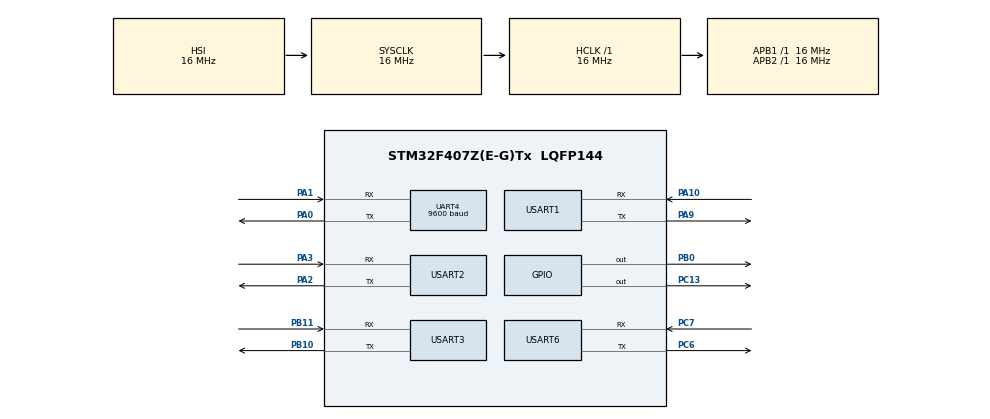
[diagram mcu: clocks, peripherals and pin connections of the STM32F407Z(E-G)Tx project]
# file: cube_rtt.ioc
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Dma.Request0=USART3_RX
Dma.Request1=UART4_RX
Dma.UART4_RX.1.Direction=DMA_PERIPH_TO_MEMORY
Dma.UART4_RX.1.FIFOMode=DMA_FIFOMODE_DISABLE
Dma.UART4_RX.1.Instance=DMA1_Stream2
Dma.UART4_RX.1.MemDataAlignment=DMA_MDATAALIGN_BYTE
Dma.UART4_RX.1.MemInc=DMA_MINC_ENABLE
Dma.UART4_RX.1.Mode=DMA_NORMAL
Dma.UART4_RX.1.PeriphDataAlignment=DMA_PDATAALIGN_BYTE
Dma.UART4_RX.1.PeriphInc=DMA_PINC_DISABLE
Dma.UART4_RX.1.Priority=DMA_PRIORITY_LOW
Dma.USART3_RX.0.Direction=DMA_PERIPH_TO_MEMORY
Dma.USART3_RX.0.FIFOMode=DMA_FIFOMODE_DISABLE
Dma.USART3_RX.0.Instance=DMA1_Stream1
Dma.USART3_RX.0.MemDataAlignment=DMA_MDATAALIGN_BYTE
Dma.USART3_RX.0.MemInc=DMA_MINC_ENABLE
Dma.USART3_RX.0.Mode=DMA_CIRCULAR
Dma.USART3_RX.0.PeriphDataAlignment=DMA_PDATAALIGN_BYTE
Dma.USART3_RX.0.PeriphInc=DMA_PINC_DISABLE
Dma.USART3_RX.0.Priority=DMA_PRIORITY_LOW
Mcu.Family=STM32F4
Mcu.Name=STM32F407Z(E-G)Tx
Mcu.Package=LQFP144
NVIC.DMA1_Stream1_IRQn=true\:0\:0\:false\:false\:true\:true\:false\:true\:true
NVIC.DMA1_Stream2_IRQn=true\:0\:0\:false\:false\:true\:true\:false\:true\:true
NVIC.PriorityGroup=NVIC_PRIORITYGROUP_4
NVIC.TIM6_DAC_IRQn=true\:15\:0\:false\:false\:true\:false\:false\:true\:true
NVIC.TimeBase=TIM6_DAC_IRQn
NVIC.TimeBaseIP=TIM6
NVIC.UART4_IRQn=true\:0\:0\:false\:false\:true\:false\:true\:true\:true
NVIC.USART3_IRQn=true\:0\:0\:false\:false\:true\:false\:true\:true\:true
NVIC.USART6_IRQn=true\:0\:0\:false\:false\:true\:false\:true\:true\:true
PA0-WKUP.Mode=Asynchronous
PA0-WKUP.Signal=UART4_TX
PA1.Mode=Asynchronous
PA1.Signal=UART4_RX
PA10.Mode=Asynchronous
PA10.Signal=USART1_RX
PA13.Mode=Serial_Wire
PA13.Signal=SYS_JTMS-SWDIO
PA14.Mode=Serial_Wire
PA14.Signal=SYS_JTCK-SWCLK
PA2.Mode=Asynchronous
PA2.Signal=USART2_TX
PA3.Mode=Asynchronous
PA3.Signal=USART2_RX
PA9.Mode=Asynchronous
PA9.Signal=USART1_TX
PB0.Signal=GPIO_Output
PB10.Mode=Asynchronous
PB10.Signal=USART3_TX
PB11.Mode=Asynchronous
PB11.Signal=USART3_RX
PC13-ANTI_TAMP.PinState=GPIO_PIN_SET
PC13-ANTI_TAMP.Signal=GPIO_Output
PC6.Mode=Asynchronous
PC6.Signal=USART6_TX
PC7.Mode=Asynchronous
PC7.Signal=USART6_RX
ProjectManager.HeapSize=0x200
ProjectManager.StackSize=0x400
ProjectManager.TargetToolchain=MDK-ARM V5.32
RCC.AHBFreq_Value=16000000
RCC.APB1Freq_Value=16000000
RCC.APB2Freq_Value=16000000
RCC.CortexFreq_Value=16000000
RCC.HSE_VALUE=25000000
RCC.HSI_VALUE=16000000
RCC.LSE_VALUE=32768
RCC.SYSCLKFreq_VALUE=16000000
RCC.VCOOutputFreq_Value=192000000
RealThread.X-CUBE-RT-Thread_Nano.4.1.1.RTAaThreadCcRTOSJjkernel=true
RealThread.X-CUBE-RT-Thread_Nano.4.1.1.RTAaThreadCcRTOSJjlibcpu=true
RealThread.X-CUBE-RT-Thread_Nano.4.1.1.RTAaThreadCcRTOSJjshell=true
RealThread.X-CUBE-RT-Thread_Nano.4.1.1.RT_USING_HEAP=1
RealThread.X-CUBE-RT-Thread_Nano.4.1.1.RT_USING_MUTEX=1
RealThread.X-CUBE-RT-Thread_Nano.4.1.1.RT_USING_SMALL_MEM=1
RealThread.X-CUBE-RT-Thread_Nano.4.1.1.RT_USING_SMALL_MEM_AS_HEAP=1
UART4.BaudRate=9600
UART4.VirtualMode=Asynchronous
USART1.VirtualMode=VM_ASYNC
USART2.VirtualMode=VM_ASYNC
USART3.VirtualMode=VM_ASYNC
USART6.VirtualMode=VM_ASYNC
VP_RealThread.X-CUBE-RT-Thread_Nano_VS_RTOSJjRTAaThread_4.1.1_4.1.1.Mode=RTOSJjRTAaThread
VP_SYS_VS_tim6.Mode=TIM6
board=custom

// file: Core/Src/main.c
/* USER CODE BEGIN Header */
/**
  ******************************************************************************
  * @file           : main.c
  * @brief          : Main program body
  ******************************************************************************
  * @attention
  *
  * Copyright (c) 2026 STMicroelectronics.
  * All rights reserved.
  *
  * This software is licensed under terms that can be found in the LICENSE file
  * in the root directory of this software component.
  * If no LICENSE file comes with this software, it is provided AS-IS.
  *
  ******************************************************************************
  */
/* USER CODE END Header */
#include "main.h"
#include "dma.h"
#include "usart.h"
#include "gpio.h"

/* USER CODE BEGIN Includes */
#include <rtthread.h>
#include <jy61p.h>
#include <fun.h>
/* USER CODE END Includes */

void SystemClock_Config(void);

int main(void)
{

  /* MCU Configuration--------------------------------------------------------*/

  /* Reset of all peripherals, Initializes the Flash interface and the Systick. */
  HAL_Init();

  /* Configure the system clock */
  SystemClock_Config();

  /* Initialize all configured peripherals */
  MX_GPIO_Init();
  MX_DMA_Init();
  MX_USART1_UART_Init();
  MX_USART3_UART_Init();
  MX_UART4_Init();
  MX_USART2_UART_Init();
  MX_USART6_UART_Init();
  /* USER CODE BEGIN 2 */
  extern int app_init(void);
  app_init();
  /* USER CODE END 2 */

  /* Infinite loop */
  /* USER CODE BEGIN WHILE */
  while (1)
  {
	  rt_thread_mdelay(1000);
    /* USER CODE END WHILE */

  }
}

void SystemClock_Config(void)
{
  RCC_OscInitTypeDef RCC_OscInitStruct = {0};
  RCC_ClkInitTypeDef RCC_ClkInitStruct = {0};

  /** Configure the main internal regulator output voltage
  */
  __HAL_RCC_PWR_CLK_ENABLE();
  __HAL_PWR_VOLTAGESCALING_CONFIG(PWR_REGULATOR_VOLTAGE_SCALE1);

  /** Initializes the RCC Oscillators according to the specified parameters
  * in the RCC_OscInitTypeDef structure.
  */
  RCC_OscInitStruct.OscillatorType = RCC_OSCILLATORTYPE_HSI;
  RCC_OscInitStruct.HSIState = RCC_HSI_ON;
  RCC_OscInitStruct.HSICalibrationValue = RCC_HSICALIBRATION_DEFAULT;
  RCC_OscInitStruct.PLL.PLLState = RCC_PLL_NONE;
  if (HAL_RCC_OscConfig(&RCC_OscInitStruct) != HAL_OK)
  {
    Error_Handler();
  }

  /** Initializes the CPU, AHB and APB buses clocks
  */
  RCC_ClkInitStruct.ClockType = RCC_CLOCKTYPE_HCLK|RCC_CLOCKTYPE_SYSCLK
                              |RCC_CLOCKTYPE_PCLK1|RCC_CLOCKTYPE_PCLK2;
  RCC_ClkInitStruct.SYSCLKSource = RCC_SYSCLKSOURCE_HSI;
  RCC_ClkInitStruct.AHBCLKDivider = RCC_SYSCLK_DIV1;
  RCC_ClkInitStruct.APB1CLKDivider = RCC_HCLK_DIV1;
  RCC_ClkInitStruct.APB2CLKDivider = RCC_HCLK_DIV1;

  if (HAL_RCC_ClockConfig(&RCC_ClkInitStruct, FLASH_LATENCY_0) != HAL_OK)
  {
    Error_Handler();
  }
}

void HAL_TIM_PeriodElapsedCallback(TIM_HandleTypeDef *htim)
{
  if (htim->Instance == TIM6)
  {
    HAL_IncTick();
  }
}

void Error_Handler(void)
{
  __disable_irq();
  while (1)
  {
  }
}
